# Daric register map
Vendor: Daric; Series: Daric; File version: 1.0
CPU: CM7 r1p2, little endian, MPU, FPU, vendor SysTick, 3 interrupt priority bits
Registers are 32-bit, access not given, reset 0x0 unless marked. A register's access mark holds for its fields unless they carry their own. Offsets are from the block's base; [hi:lo] are bit positions; lines under a group give offsets from that group; {n}, {i} and the like mark numbered series; 'fields as' and 'values as' point back to an identical list.

## CGU — Clock Generation Unit
Base 0x40040000
0x00 CGUSEC — CGU Security Related
0x04 CGULP — CGU Low Power
0x08 CGU_SEED — CLK Cipher Seed
0x0C CGU_SEEDAR wo — CLK Cipher Seed AR
0x10 CGUSELO — CLKTOP Source Select
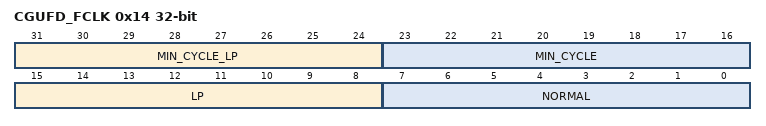
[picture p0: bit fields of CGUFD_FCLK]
0x14 CGUFD_FCLK — FCLK Freq Div
  [31:24] MIN_CYCLE_LP — Min cycle for lp
  [23:16] MIN_CYCLE
  [15:8] LP — Low power setting
  [7:0] NORMAL — Normal setting
0x18 CGUFD_ACLK — ACLK Freq Div
0x1C CGUFD_HCLK — HCLK Freq Div
0x20 CGUFD_ICLK — ICLK Freq Div
0x24 CGUFD_PCLK — PCLK Freq Div
0x28 CGUFD_AOCLK — AOCLK Freq Div
0x2C CGUSET wo — CGU Setting Enable
0x30 CGUSEL1 — CLKSYS Source Select
0x34 CGUFD_PKECLK — PKECLK Freq Div
0x38 CGUFD_AORAM — AORAM Freq Div
0x3C CGUFD_PER — CLKPER Freq Div
0x40 CGUFSFREQ0 ro — Freq Sensor FCLK/CLKPKE
0x44 CGUFSFREQ1 ro — Freq Sensor CLKAO/CLKRAM
0x48 CGUFSFREQ2 ro — Freq Sensor OSC/XTAL
0x4C CGUFSFREQ3 ro — Freq Sensor PLL0/1
0x50 CGUFSVLD ro — Freq Valid
0x54 CGUFSCR — Freq Sensor Reference
0x60 CGUACLKGR — ACLK Group Sub-gate
0x64 CGUHCLKGR — HCLK Group Sub-gate
0x68 CGUICLKGR — ICLK Group Sub-gate
0x6C CGUPCLKGR — PCLK Group Sub-gate

## RCU — Reset Controller Unit
Base 0x40040080
0x00 RCURST0 wo — Reset Chip System
0x04 RCURST1 wo — Reset Core System
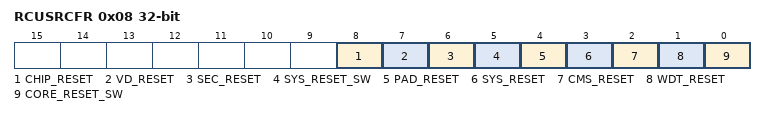
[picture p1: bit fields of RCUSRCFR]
0x08 RCUSRCFR ro — Reset Source Flags
  [8] CHIP_RESET
  [7] VD_RESET — Voltage Detector Reset
  [6] SEC_RESET — Security Reset
  [5] SYS_RESET_SW — Software System Reset
  [4] PAD_RESET
  [3] SYS_RESET — System Reset
  [2] CMS_RESET — Chip Mode Reset
  [1] WDT_RESET — Watchdog Reset
  [0] CORE_RESET_SW — Software Core Reset

## IPC — IP Control (PLL)
Base 0x40040090
0x00 IPCAR wo — IP Control AR
0x04 IPCEN — IP Control Enable
0x08 IPCLPEN — IP Low Power Enable
0x0C IPCOSC — IP OSC Control
0x10 IPCPLL_MN — PLL MN Parameter
0x14 IPCPLL_F — PLL F Parameter
0x18 IPCPLL_Q — PLL Q Parameter
0x1C IPCCR — IPC Control

## WDT — Watchdog Timer
Base 0x40041000
Same registers: WDT_AO 0x40062000
0x00 WDT_VAL — Load value
0x04 WDT_CNT — Counter value
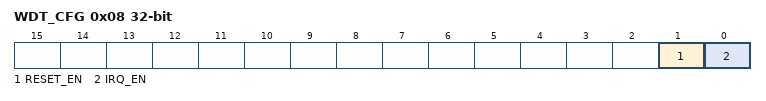
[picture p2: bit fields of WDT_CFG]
0x08 WDT_CFG — Configuration
  [1] RESET_EN, [0] IRQ_EN
0x0C WDT_CLR wo — Clear counter
0x10 WDT_INTRAW ro — Raw Interrupt
0x14 WDT_INT ro — Masked Interrupt
0xC00 WDT_LOCKCR — Lock Configuration
0xF00 WDT_ITCR — Internal Test Config
0xF04 WDT_ITOP — Internal Test Op

## DUART — Debug UART
Base 0x40042000
0x00 TXDATA
0x04 TXEN — TX Enable
  [0] EN
0x08 BUSY ro — Busy Status
  [0] BUSY
0x0C ETU — TX ETU

## EVC — Event Controller
Base 0x40044000
{0x0+4i} CM7EVSEL[{i}] (i=0..7) — CM7 Event Select
0x20 CM7_EVEN — CM7 Event Enable
0x24 CM7_EVFR — CM7 Event Flag
0x30 TMREVSEL — Timer Event Select
0x34 TMR_EVEN — Timer Event Enable
{0x40+4i} IF_EVEN[{i}] (i=0..7) — Interface Event Enable
{0x60+4i} IF_EVERR_FR[{i}] (i=0..7) — Interface Event Error Flag
0x80 CM7_ERRFR — CM7 Error Flag
0x84 CM7_ERRCR — CM7 Error Enable
{0x90+4i} RRCEVSEL[{i}] (i=0..3) — RRC Event Select
0xA0 RRC_EVEN — RRC Event Enable

## UART0 — UART0 Interface
Base 0x50101000
Same registers: UART1 0x50102000, UART2 0x50103000, UART3 0x50104000
0x00 RX_CHANNEL group — UDMA RX Channel Registers
  0x00 SADDR — RX Buffer Start Address
  0x04 SIZE — RX Buffer Size
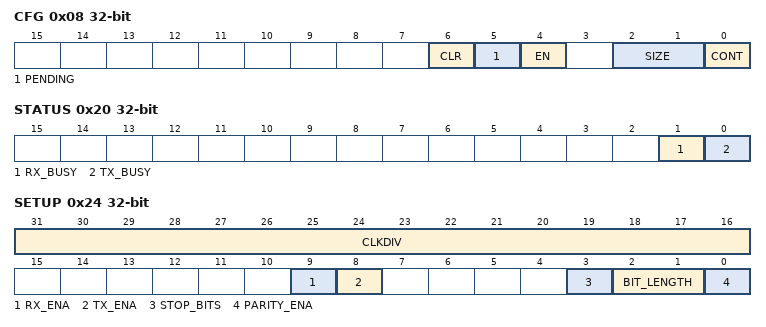
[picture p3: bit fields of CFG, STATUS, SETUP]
  0x08 CFG — RX Configuration
    [6] CLR — Clear Channel
    [5] PENDING — Transfer Pending Status
    [4] EN — Enable Channel
    [2:1] SIZE — Data Size (00=8bit, 01=16bit, 10=32bit)
    [0] CONT — Continuous Mode
0x10 TX_CHANNEL group — UDMA TX Channel Registers
  0x00 SADDR — TX Buffer Start Address
  0x04 SIZE — TX Buffer Size
  0x08 CFG — TX Configuration
    fields as RX_CHANNEL.CFG
0x20 STATUS — UART Status Register
  [1] RX_BUSY, [0] TX_BUSY
0x24 SETUP — UART Setup Register
  [31:16] CLKDIV, [9] RX_ENA, [8] TX_ENA, [3] STOP_BITS, [2:1] BIT_LENGTH, [0] PARITY_ENA
0x28 ERROR — UART Error Register
0x2C IRQ_EN — UART IRQ Enable Register
